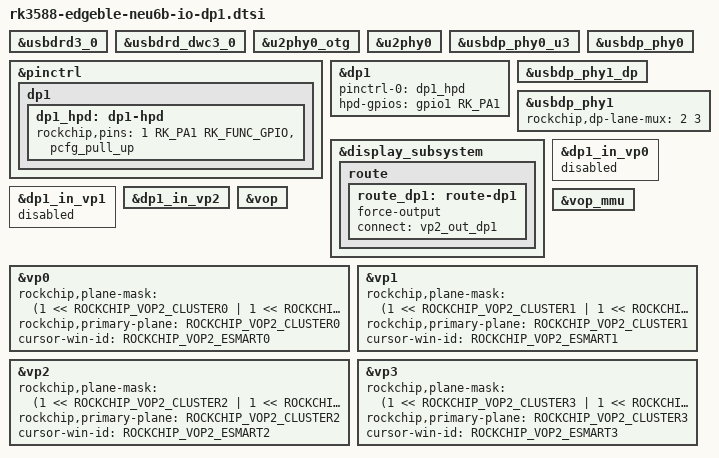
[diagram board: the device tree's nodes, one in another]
// SPDX-License-Identifier: (GPL-2.0+ OR MIT)
/*
 * Copyright (c) 2023 Edgeble AI Technologies Pvt. Ltd.
 */

&usbdrd3_0 {
	status = "okay";
};

/* OTG, set dr_mode = "host"; for host */
&usbdrd_dwc3_0 {
	status = "okay";
};

&u2phy0_otg {
	status = "okay";
};

&u2phy0 {
	status = "okay";
};

&usbdp_phy0_u3 {
	status = "okay";
};

&usbdp_phy0 {
	status = "okay";
};

/* DP1 */
&pinctrl {
	dp1 {
		dp1_hpd: dp1-hpd {
			rockchip,pins = <1 RK_PA1 RK_FUNC_GPIO &pcfg_pull_up>;
		};
	};
};

&dp1 {
	status = "okay";
	pinctrl-names = "default";
	pinctrl-0 = <&dp1_hpd>;
	hpd-gpios = <&gpio1 RK_PA1 GPIO_ACTIVE_HIGH>; /* DP2_HPDIN_M0 */
};

&usbdp_phy1_dp {
	status = "okay";
};

&usbdp_phy1 {
	status = "okay";
	rockchip,dp-lane-mux = < 2 3 >;
};

&display_subsystem {
	route {
		route_dp1: route-dp1 {
			status = "okay";
			force-output;
			connect = <&vp2_out_dp1>;
		};
	};
};

&dp1_in_vp0 {
	status = "disabled";
};

&dp1_in_vp1 {
	status = "disabled";
};

&dp1_in_vp2 {
	status = "okay";
};

&vop {
	status = "okay";
};

&vop_mmu {
	status = "okay";
};

/* vp0 & vp1 splice for 8K output */
&vp0 {
	rockchip,plane-mask = <(1 << ROCKCHIP_VOP2_CLUSTER0 | 1 << ROCKCHIP_VOP2_ESMART0)>;
	rockchip,primary-plane = <ROCKCHIP_VOP2_CLUSTER0>;
	cursor-win-id = <ROCKCHIP_VOP2_ESMART0>;
};

&vp1 {
	rockchip,plane-mask = <(1 << ROCKCHIP_VOP2_CLUSTER1 | 1 << ROCKCHIP_VOP2_ESMART1)>;
	rockchip,primary-plane = <ROCKCHIP_VOP2_CLUSTER1>;
	cursor-win-id = <ROCKCHIP_VOP2_ESMART1>;
};

&vp2 {
	rockchip,plane-mask = <(1 << ROCKCHIP_VOP2_CLUSTER2 | 1 << ROCKCHIP_VOP2_ESMART2)>;
	rockchip,primary-plane = <ROCKCHIP_VOP2_CLUSTER2>;
	cursor-win-id = <ROCKCHIP_VOP2_ESMART2>;
};

&vp3 {
	rockchip,plane-mask = <(1 << ROCKCHIP_VOP2_CLUSTER3 | 1 << ROCKCHIP_VOP2_ESMART3)>;
	rockchip,primary-plane = <ROCKCHIP_VOP2_CLUSTER3>;
	cursor-win-id = <ROCKCHIP_VOP2_ESMART3>;
};
